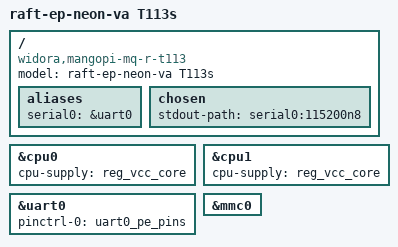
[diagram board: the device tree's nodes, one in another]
// SPDX-License-Identifier: (GPL-2.0+ OR MIT)
// Copyright (C) 2022 Arm Ltd.

#include <dt-bindings/interrupt-controller/irq.h>

/dts-v1/;

#include "sun8i-t113s.dtsi"
#include "sunxi-d1s-t113-mangopi-mq-r.dtsi"

/ {
	model = "raft-ep-neon-va T113s";
	compatible = "widora,mangopi-mq-r-t113", "allwinner,sun8i-t113s";

	aliases {
                serial0 = &uart0;
	};

        chosen {
               stdout-path = "serial0:115200n8";
        };
};

&cpu0 {
	cpu-supply = <&reg_vcc_core>;
};

&cpu1 {
	cpu-supply = <&reg_vcc_core>;
};

&uart0 {
	pinctrl-names = "default";
	pinctrl-0 = <&uart0_pe_pins>;
	status = "okay";
};

&mmc0 {
      /delete-property/ cd-gpios;
};
